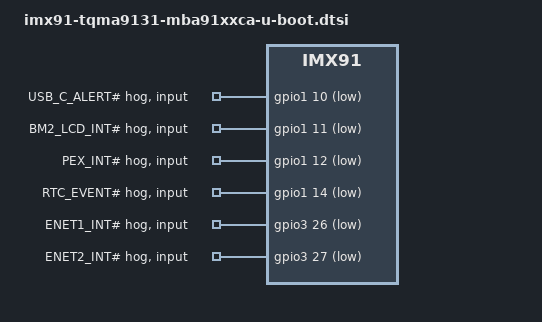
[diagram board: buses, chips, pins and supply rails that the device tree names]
// SPDX-License-Identifier: (GPL-2.0-or-later OR MIT)
/*
 * Copyright (c) 2024 TQ-Systems GmbH <u-boot@ew.tq-group.com>,
 * D-82229 Seefeld, Germany.
 * Author: Markus Niebel
 */

/*
 * include the generic, SOM specific part of U-Boot modifications
 * for device tree
 */
#include "imx91-tqma9131-u-boot.dtsi"

/ {
	aliases {
		usbgadget0 = &usbg1;
	};

	config {
		u-boot,mmc-env-offset = <0x400000>;
		u-boot,mmc-env-offset-redundant = <0x410000>;
	};

	usbg1: usbg1 {
		compatible = "fsl,imx27-usb-gadget";
		dr_mode = "peripheral";
		chipidea,usb = <&usbotg1>;
	};
};

&gpio1 {
	tcpc-irq-hog {
		gpio-hog;
		gpios = <10 GPIO_ACTIVE_LOW>;
		input;
		line-name = "USB_C_ALERT#";
	};

	lcd-int-hog {
		gpio-hog;
		gpios = <11 GPIO_ACTIVE_LOW>;
		input;
		line-name = "BM2_LCD_INT#";
	};

	expander-irq-hog {
		gpio-hog;
		gpios = <12 GPIO_ACTIVE_LOW>;
		input;
		line-name = "PEX_INT#";
	};

	rtc-irq-hog {
		gpio-hog;
		gpios = <14 GPIO_ACTIVE_LOW>;
		input;
		line-name = "RTC_EVENT#";
	};
};

&gpio3 {
	ethphy-eqos-irq-hog {
		gpio-hog;
		gpios = <26 GPIO_ACTIVE_LOW>;
		input;
		line-name = "ENET1_INT#";
	};

	ethphy-fec-irq-hog {
		gpio-hog;
		gpios = <27 GPIO_ACTIVE_LOW>;
		input;
		line-name = "ENET2_INT#";
	};
};

&lpuart1 {
	bootph-pre-ram;
	bootph-some-ram;
};

&pinctrl_uart1 {
	bootph-pre-ram;
	bootph-some-ram;
};

&reg_usdhc2_vmmc {
	u-boot,off-on-delay-us = <20000>;
};

&ptn5110 {
	status = "disabled";
};

&usbotg1 {
	extcon = <&ptn5110>;
};

&usdhc2 {
	fsl,signal-voltage-switch-extra-delay-ms = <8>;
	sd-uhs-sdr104;
	sd-uhs-ddr50;
};

&wdog3 {
	u-boot,noautostart;
	timeout-sec = <60>;
};
